# EFR32MG26B611F2048IM48 register map
Vendor: Silicon Labs; Series: EFR32; File version: B
Registers are 32-bit, read-write, reset 0x0 unless marked. A register's access mark holds for its fields unless they carry their own. Offsets are from the block's base; [hi:lo] are bit positions; {n}, {i} and the like mark numbered series.

## PRS_NS — PRS_NS Registers
Base 0x50038000
Same registers: PRS_S 0x40038000
0x00 IPVERSION ro reset 0x6
  [31:0] IPVERSION — IP version ID
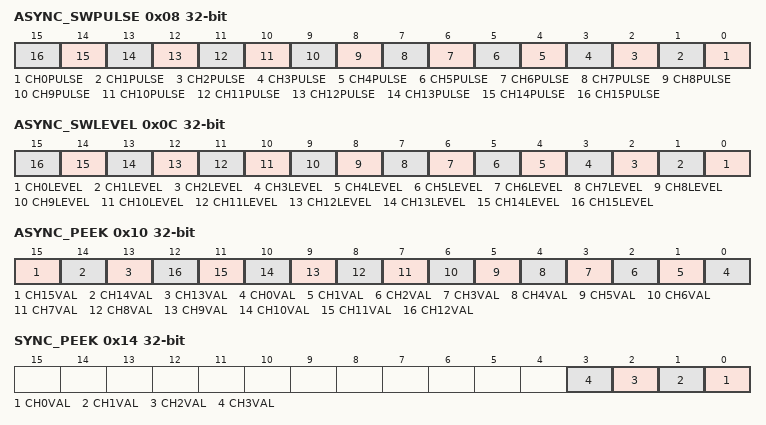
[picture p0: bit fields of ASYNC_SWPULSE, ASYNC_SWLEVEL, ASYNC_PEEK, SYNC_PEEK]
0x08 ASYNC_SWPULSE wo
  [n] CH{n}PULSE (n=0..15) — Channel pulse
0x0C ASYNC_SWLEVEL
  [n] CH{n}LEVEL (n=0..15) — Channel Level
0x10 ASYNC_PEEK ro
  [15] CH15VAL — Channel 15 current value
  [14] CH14VAL — Channel 14 current value
  [13] CH13VAL — Channel 13 current value
  [n] CH{n}VAL (n=0..12) — Channel {n} Current Value
0x14 SYNC_PEEK ro
  [n] CH{n}VAL (n=0..3) — Channel Value
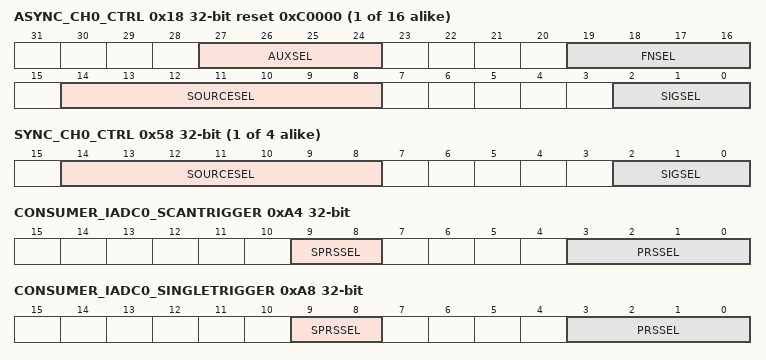
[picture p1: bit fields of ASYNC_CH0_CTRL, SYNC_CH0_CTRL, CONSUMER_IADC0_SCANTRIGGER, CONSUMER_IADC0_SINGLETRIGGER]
{0x18+4i} ASYNC_CH{i}_CTRL reset 0xC0000 (i=0..15)
  [27:24] AUXSEL — Auxiliary LUT Input Select
  [19:16] FNSEL — Function Select
    0=LOGICAL_ZERO (Logical 0); 1=A_NOR_B; 2=NOT_A_AND_B ((!A) AND B); 3=NOT_A (!A); 4=A_AND_NOT_B (A AND (!B)); 5=NOT_B (!B); 6=A_XOR_B; 7=A_NAND_B; 8=A_AND_B; 9=A_XNOR_B; 10=B; 11=NOT_A_OR_B ((!A) OR B); 12=A; 13=A_OR_NOT_B (A OR (!B)); 14=A_OR_B; 15=LOGICAL_ONE (Logical 1)
  [14:8] SOURCESEL — Source Select
  [2:0] SIGSEL — Signal Select
    0=NONE
{0x58+4i} SYNC_CH{i}_CTRL (i=0..3)
  [14:8] SOURCESEL — Source Select
  [2:0] SIGSEL — Signal Select
    0=NONE
0x68 CONSUMER_CMU_CALDN — CALDN consumer register
  [3:0] PRSSEL — CALDN async channel select
0x6C CONSUMER_CMU_CALUP — CALUP Consumer register
  [3:0] PRSSEL — CALUP async channel select
{0x70+0xC*i} CONSUMER_EUSART{i}_CLK (i=0..3) — CLK consumer register
  [3:0] PRSSEL — CLK async channel select
{0x74+0xC*i} CONSUMER_EUSART{i}_RX (i=0..3) — RX Consumer register
  [3:0] PRSSEL — RX async channel select
{0x78+0xC*i} CONSUMER_EUSART{i}_TRIGGER (i=0..3) — TRIGGER Consumer register
  [3:0] PRSSEL — TRIGGER async channel select
0xA4 CONSUMER_IADC0_SCANTRIGGER — SCAN consumer register
  [9:8] SPRSSEL — SCAN sync channel select
  [3:0] PRSSEL — SCAN async channel select
0xA8 CONSUMER_IADC0_SINGLETRIGGER — SINGLE Consumer register
  [9:8] SPRSSEL — SINGLE sync channel select
  [3:0] PRSSEL — SINGLE async channel select
0xAC CONSUMER_LDMAXBAR_DMAREQ0 — DMAREQ0 consumer register
  [3:0] PRSSEL — DMAREQ0 async channel select
0xB0 CONSUMER_LDMAXBAR_DMAREQ1 — DMAREQ1 Consumer register
  [3:0] PRSSEL — DMAREQ1 async channel select
0xB4 CONSUMER_LETIMER0_CLEAR — CLEAR consumer register
  [3:0] PRSSEL — CLEAR async channel select
0xB8 CONSUMER_LETIMER0_START — START Consumer register
  [3:0] PRSSEL — START async channel select
0xBC CONSUMER_LETIMER0_STOP — STOP Consumer register
  [3:0] PRSSEL — STOP async channel select
0xC0 CONSUMER_MODEM_DIN — DIN consumer register
  [3:0] PRSSEL — DIN async channel select
0xC4 CONSUMER_MODEM_PAEN — PAEN Consumer register
  [3:0] PRSSEL — PAEN async channel select
0xC8 CONSUMER_PCNT0_S0IN — S0IN consumer register
  [3:0] PRSSEL — S0IN async channel select
0xCC CONSUMER_PCNT0_S1IN — S1IN Consumer register
  [3:0] PRSSEL — S1IN async channel select
0xFC CONSUMER_RAC_CLR — CLR consumer register
  [3:0] PRSSEL — CLR async channel select
{0x100+4i} CONSUMER_RAC_CTIIN{i} (i=0..3) — CTI Consumer register
  [3:0] PRSSEL — CTI async channel select
0x110 CONSUMER_RAC_FORCETX — FORCETX Consumer register
  [3:0] PRSSEL — FORCETX async channel select
0x114 CONSUMER_RAC_RXDIS — RXDIS Consumer register
  [3:0] PRSSEL — RXDIS async channel select
0x118 CONSUMER_RAC_RXEN — RXEN Consumer register
  [3:0] PRSSEL — RXEN async channel select
0x11C CONSUMER_RAC_TXEN — TXEN Consumer register
  [3:0] PRSSEL — TXEN async channel select
0x120 CONSUMER_SETAMPER_TAMPERSRC25 — TAMPERSRC25 consumer register
  [3:0] PRSSEL — TAMPERSRC25 async channel select
{0xBC+4i} CONSUMER_SETAMPER_TAMPERSRC{i} (i=26..31) — TAMPERSRC{i} Consumer register
  [3:0] PRSSEL — TAMPERSRC{i} async channel select
0x13C CONSUMER_SYSRTC0_IN0 — IN0 consumer register
  [3:0] PRSSEL — IN0 async channel select
0x140 CONSUMER_SYSRTC0_IN1 — IN1 Consumer register
  [3:0] PRSSEL — IN1 async channel select
0x144 CONSUMER_HFXO0_OSCREQ — OSCREQ consumer register
  [3:0] PRSSEL — OSC async channel select
0x148 CONSUMER_HFXO0_TIMEOUT — TIMEOUT Consumer register
  [3:0] PRSSEL — TIMEOUT async channel select
0x14C CONSUMER_CORE_CTIIN0 — CTI0 consumer register
  [3:0] PRSSEL — CTI async channel select
{0x14C+4i} CONSUMER_CORE_CTIIN{i} (i=1..3) — CTI{i} Consumer register
  [3:0] PRSSEL — CTI async channel select
0x15C CONSUMER_CORE_M33RXEV — M33 Consumer register
  [3:0] PRSSEL — M33 async channel select
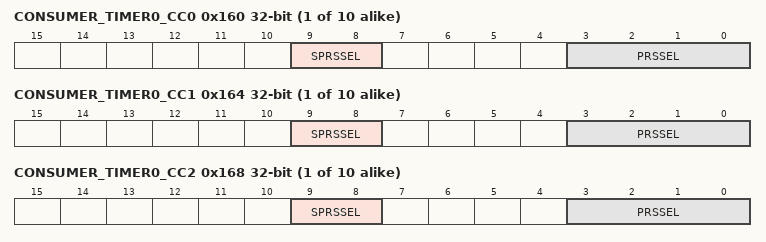
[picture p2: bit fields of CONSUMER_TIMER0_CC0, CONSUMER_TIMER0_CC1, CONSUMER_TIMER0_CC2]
{0x160+0x18*i} CONSUMER_TIMER{i}_CC0 (i=0..9) — CC0 consumer register
  [9:8] SPRSSEL — CC0 sync channel select
  [3:0] PRSSEL — CC0 async channel select
{0x164+0x18*i} CONSUMER_TIMER{i}_CC1 (i=0..9) — CC1 Consumer register
  [9:8] SPRSSEL — CC1 sync channel select
  [3:0] PRSSEL — CC1 async channel select
{0x168+0x18*i} CONSUMER_TIMER{i}_CC2 (i=0..9) — CC2 Consumer register
  [9:8] SPRSSEL — CC2 sync channel select
  [3:0] PRSSEL — CC2 async channel select
{0x16C+0x18*i} CONSUMER_TIMER{i}_DTI (i=0..9) — DTI Consumer register
  [3:0] PRSSEL — DTI async channel select
{0x170+0x18*i} CONSUMER_TIMER{i}_DTIFS1 (i=0..9) — DTI Consumer register
  [3:0] PRSSEL — DTI async channel select
{0x174+0x18*i} CONSUMER_TIMER{i}_DTIFS2 (i=0..9) — DTI Consumer register
  [3:0] PRSSEL — DTI async channel select
{0x250+0x1C*i} CONSUMER_USART{i}_CLK (i=0..2) — CLK consumer register
  [3:0] PRSSEL — CLK async channel select
{0x254+0x1C*i} CONSUMER_USART{i}_IR (i=0..2) — IR Consumer register
  [3:0] PRSSEL — IR async channel select
{0x258+0x1C*i} CONSUMER_USART{i}_RX (i=0..2) — RX Consumer register
  [3:0] PRSSEL — RX async channel select
{0x25C+0x1C*i} CONSUMER_USART{i}_TRIGGER (i=0..2) — TRIGGER Consumer register
  [3:0] PRSSEL — TRIGGER async channel select
0x2A4 CONSUMER_VDAC0_ASYNCTRIGCH0 — ASYNCTRIG consumer register
  [3:0] PRSSEL — ASYNCTRIG async channel select
0x2A8 CONSUMER_VDAC0_ASYNCTRIGCH1 — ASYNCTRIG Consumer register
  [3:0] PRSSEL — ASYNCTRIG async channel select
0x2AC CONSUMER_VDAC0_SYNCTRIGCH0 — SYNCTRIG Consumer register
  [9:8] SPRSSEL — SYNCTRIG sync channel select
0x2B0 CONSUMER_VDAC0_SYNCTRIGCH1 — SYNCTRIG Consumer register
  [9:8] SPRSSEL — SYNCTRIG sync channel select
0x2B4 CONSUMER_VDAC1_ASYNCTRIGCH0 — ASYNCTRIG consumer register
  [3:0] PRSSEL — ASYNCTRIG async channel select
0x2B8 CONSUMER_VDAC1_ASYNCTRIGCH1 — ASYNCTRIG Consumer register
  [3:0] PRSSEL — ASYNCTRIG async channel select
0x2BC CONSUMER_VDAC1_SYNCTRIGCH0 — SYNCTRIG Consumer register
  [9:8] SPRSSEL — SYNCTRIG sync channel select
0x2C0 CONSUMER_VDAC1_SYNCTRIGCH1 — SYNCTRIG Consumer register
  [9:8] SPRSSEL — SYNCTRIG sync channel select
0x2C4 CONSUMER_WDOG0_SRC0 — SRC0 consumer register
  [3:0] PRSSEL — SRC0 async channel select
0x2C8 CONSUMER_WDOG0_SRC1 — SRC1 Consumer register
  [3:0] PRSSEL — SRC1 async channel select
0x2CC CONSUMER_WDOG1_SRC0 — SRC0 consumer register
  [3:0] PRSSEL — SRC0 async channel select
0x2D0 CONSUMER_WDOG1_SRC1 — SRC1 Consumer register
  [3:0] PRSSEL — SRC1 async channel select
